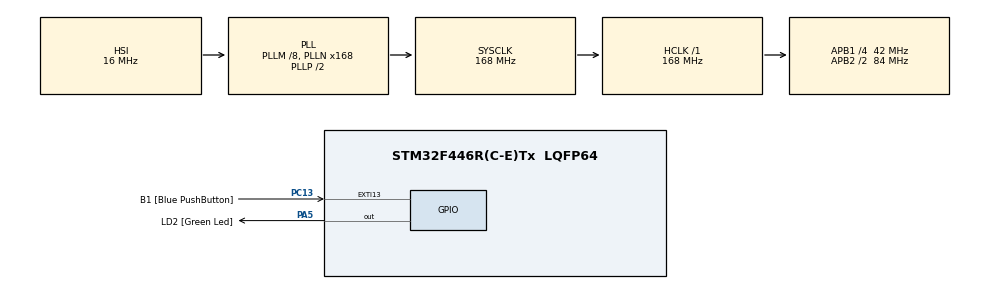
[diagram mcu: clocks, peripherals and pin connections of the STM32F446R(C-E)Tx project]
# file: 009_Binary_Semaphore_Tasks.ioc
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Mcu.Family=STM32F4
Mcu.Name=STM32F446R(C-E)Tx
Mcu.Package=LQFP64
NVIC.PriorityGroup=NVIC_PRIORITYGROUP_4
NVIC.TIM5_IRQn=true\:0\:0\:false\:false\:true\:false\:true\:true
NVIC.TimeBase=TIM5_IRQn
NVIC.TimeBaseIP=TIM5
PA13.GPIO_Label=TMS
PA13.Signal=SYS_JTMS-SWDIO
PA14.GPIO_Label=TCK
PA14.Signal=SYS_JTCK-SWCLK
PA2.GPIO_Label=USART_TX
PA2.Signal=USART2_TX
PA3.GPIO_Label=USART_RX
PA3.Signal=USART2_RX
PA5.GPIO_Label=LD2 [Green Led]
PA5.Signal=GPIO_Output
PB3.GPIO_Label=SWO
PB3.Signal=SYS_JTDO-SWO
PC13.GPIO_Label=B1 [Blue PushButton]
PC13.GPIO_ModeDefaultEXTI=GPIO_MODE_IT_FALLING
PC13.Signal=GPXTI13
PC14-OSC32_IN.Signal=RCC_OSC32_IN
PC15-OSC32_OUT.Signal=RCC_OSC32_OUT
PH0-OSC_IN.Signal=RCC_OSC_IN
PH1-OSC_OUT.Signal=RCC_OSC_OUT
ProjectManager.HeapSize=0x200
ProjectManager.StackSize=0x400
ProjectManager.TargetToolchain=STM32CubeIDE
RCC.AHBFreq_Value=168000000
RCC.APB1CLKDivider=RCC_HCLK_DIV4
RCC.APB1Freq_Value=42000000
RCC.APB1TimFreq_Value=84000000
RCC.APB2CLKDivider=RCC_HCLK_DIV2
RCC.APB2Freq_Value=84000000
RCC.APB2TimFreq_Value=168000000
RCC.CortexFreq_Value=168000000
RCC.FLatency-AdvancedSettings=FLASH_LATENCY_5
RCC.HCLKFreq_Value=168000000
RCC.HSE_VALUE=8000000
RCC.HSI_VALUE=16000000
RCC.LSE_VALUE=32768
RCC.PLLM=8
RCC.PLLN=168
RCC.SYSCLKFreq_VALUE=168000000
RCC.SYSCLKSource=RCC_SYSCLKSOURCE_PLLCLK
RCC.USBFreq_Value=168000000
RCC.VCOOutputFreq_Value=336000000
VP_SYS_VS_tim5.Mode=TIM5
board=NUCLEO-F446RE

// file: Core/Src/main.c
/* USER CODE BEGIN Header */
/**
  ******************************************************************************
  * @file           : main.c
  * @brief          : Main program body
  ******************************************************************************
  * @attention
  *
  * Copyright (c) 2023 STMicroelectronics.
  * All rights reserved.
  *
  * This software is licensed under terms that can be found in the LICENSE file
  * in the root directory of this software component.
  * If no LICENSE file comes with this software, it is provided AS-IS.
  *
  ******************************************************************************
  */
/* USER CODE END Header */
#include "main.h"

/* USER CODE BEGIN PD */

//#define DWT_CTRL    (*(volatile uint32_t*)0xE0001000)

/* USER CODE END PD */

void SystemClock_Config(void);
static void MX_GPIO_Init(void);
/* USER CODE BEGIN PFP */

//function prototypes
//static void prvSetupHardware(void);
//void printmsg(char *msg);
//static void prvSetupUart(void);
//void prvSetupGpio(void);

// Task Creation
TaskHandle_t xTaskHandleM=NULL;
TaskHandle_t xTaskHandleE=NULL;
void vManagerTask(void* pvParameters);
void vEmployeeTask(void* pvParameters);

// Binary Semaphore used to Synchronization of Manager and Employee
xSemaphoreHandle xWork;

// Queue for the Manager to put the work ticket id
xQueueHandle xWorkQueue;

char* usr_msg[250] = {0};

/* USER CODE END PFP */

int main(void)
{

  /* MCU Configuration--------------------------------------------------------*/

  /* Reset of all peripherals, Initializes the Flash interface and the Systick. */
  HAL_Init();

  /* Configure the system clock */
  SystemClock_Config();

  /* Initialize all configured peripherals */
  MX_GPIO_Init();
  /* USER CODE BEGIN 2 */

  // Segger event time stamp
  DWT->CTRL |= (1 << 0);

  // Reset the RCC clock configuration to default reset state
  RCC_DeInit();

  // Update the SystemCoreClock variable
  SystemCoreClockUpdate();

//  prvSetupHardware();

  // Start Recording
//  SEGGER_SYSVIEW_Conf();
//  SEGGER_SYSVIEW_Start();

  sprintf(usr_msg, "Demo of Binary Semaphore usage between 2 Tasks \r\n");
  printf(usr_msg);

  // Explicitly Created Semaphore
  vSemaphoreCreateBinary(xWork);

  // Queue is created to hold a maximum of 1 Element
  xWorkQueue = xQueueCreate( 1, sizeof(unsigned int));

  // Check the Semaphore and Queue was created successfully
  if( (xWork != NULL) && (xWorkQueue != NULL)){

	  // Create the Manager Task
	  xTaskCreate( vManagerTask, "Manager", 500, NULL, 3, NULL);

	  // Create a Employee Task
	  xTaskCreate( vEmployeeTask, "Employee", 500, NULL, 1, NULL);

	  // Start the Scheduler
	  vTaskStartScheduler();
  }

  sprintf(usr_msg, "Queue/Sema create failed.. \r\n");
  printf(usr_msg);

  /* USER CODE END 2 */

  /* Infinite loop */
  while (1)
  {

  }
}

void SystemClock_Config(void)
{
  RCC_OscInitTypeDef RCC_OscInitStruct = {0};
  RCC_ClkInitTypeDef RCC_ClkInitStruct = {0};

  /** Configure the main internal regulator output voltage
  */
  __HAL_RCC_PWR_CLK_ENABLE();
  __HAL_PWR_VOLTAGESCALING_CONFIG(PWR_REGULATOR_VOLTAGE_SCALE1);

  /** Initializes the RCC Oscillators according to the specified parameters
  * in the RCC_OscInitTypeDef structure.
  */
  RCC_OscInitStruct.OscillatorType = RCC_OSCILLATORTYPE_HSI;
  RCC_OscInitStruct.HSIState = RCC_HSI_ON;
  RCC_OscInitStruct.HSICalibrationValue = RCC_HSICALIBRATION_DEFAULT;
  RCC_OscInitStruct.PLL.PLLState = RCC_PLL_ON;
  RCC_OscInitStruct.PLL.PLLSource = RCC_PLLSOURCE_HSI;
  RCC_OscInitStruct.PLL.PLLM = 8;
  RCC_OscInitStruct.PLL.PLLN = 168;
  RCC_OscInitStruct.PLL.PLLP = RCC_PLLP_DIV2;
  RCC_OscInitStruct.PLL.PLLQ = 2;
  RCC_OscInitStruct.PLL.PLLR = 2;
  if (HAL_RCC_OscConfig(&RCC_OscInitStruct) != HAL_OK)
  {
    Error_Handler();
  }

  /** Initializes the CPU, AHB and APB buses clocks
  */
  RCC_ClkInitStruct.ClockType = RCC_CLOCKTYPE_HCLK|RCC_CLOCKTYPE_SYSCLK
                              |RCC_CLOCKTYPE_PCLK1|RCC_CLOCKTYPE_PCLK2;
  RCC_ClkInitStruct.SYSCLKSource = RCC_SYSCLKSOURCE_PLLCLK;
  RCC_ClkInitStruct.AHBCLKDivider = RCC_SYSCLK_DIV1;
  RCC_ClkInitStruct.APB1CLKDivider = RCC_HCLK_DIV4;
  RCC_ClkInitStruct.APB2CLKDivider = RCC_HCLK_DIV2;

  if (HAL_RCC_ClockConfig(&RCC_ClkInitStruct, FLASH_LATENCY_5) != HAL_OK)
  {
    Error_Handler();
  }
}

static void MX_GPIO_Init(void)
{
  GPIO_InitTypeDef GPIO_InitStruct = {0};

  /* GPIO Ports Clock Enable */
  __HAL_RCC_GPIOC_CLK_ENABLE();
  __HAL_RCC_GPIOH_CLK_ENABLE();
  __HAL_RCC_GPIOA_CLK_ENABLE();
  __HAL_RCC_GPIOB_CLK_ENABLE();

  /*Configure GPIO pin Output Level */
  HAL_GPIO_WritePin(LD2_GPIO_Port, LD2_Pin, GPIO_PIN_RESET);

  /*Configure GPIO pin : B1_Pin */
  GPIO_InitStruct.Pin = B1_Pin;
  GPIO_InitStruct.Mode = GPIO_MODE_IT_FALLING;
  GPIO_InitStruct.Pull = GPIO_NOPULL;
  HAL_GPIO_Init(B1_GPIO_Port, &GPIO_InitStruct);

  /*Configure GPIO pins : USART_TX_Pin USART_RX_Pin */
  GPIO_InitStruct.Pin = USART_TX_Pin|USART_RX_Pin;
  GPIO_InitStruct.Mode = GPIO_MODE_AF_PP;
  GPIO_InitStruct.Pull = GPIO_NOPULL;
  GPIO_InitStruct.Speed = GPIO_SPEED_FREQ_VERY_HIGH;
  GPIO_InitStruct.Alternate = GPIO_AF7_USART2;
  HAL_GPIO_Init(GPIOA, &GPIO_InitStruct);

  /*Configure GPIO pin : LD2_Pin */
  GPIO_InitStruct.Pin = LD2_Pin;
  GPIO_InitStruct.Mode = GPIO_MODE_OUTPUT_PP;
  GPIO_InitStruct.Pull = GPIO_NOPULL;
  GPIO_InitStruct.Speed = GPIO_SPEED_FREQ_LOW;
  HAL_GPIO_Init(LD2_GPIO_Port, &GPIO_InitStruct);

}

/* USER CODE BEGIN 4 */

void vManagerTask( void* pvParameters){

	unsigned int xWorkTicketId;
	portBASE_TYPE xStatus;

	// Semaphore is created as empty state so it needs to be "given" first
	xSemaphoreGive(xWork);

	while(1){

		// get a work ticket id
		xWorkTicketId = ( rand() & 0x1FF );

		// Send work ticket id to the work queue
		xStatus = xQueueSend( xWorkQueue, &xWorkTicketId, portMAX_DELAY);

		if( xStatus != pdPASS){
			sprintf(usr_msg, "Could not send to the queue.\r\n");
			printf(usr_msg);
		}else{
			// Manager Notifying the Employee by "Giving Semaphore
			xSemaphoreGive(xWork);
			// After assigning the work yeild the processor
			taskYIELD();
		}
	}
}

void EmployeeDoWork(unsigned char TicketId){

	// Implement the work according to the TicketId
	sprintf(usr_msg, "Employee Task: Working on Ticket Id: %d\r\n", TicketId);
	printf(usr_msg);
	vTaskDelay(TicketId);
}

void vEmployeeTask(void* pvParameters){

	unsigned char xWorkTicketId;
	portBASE_TYPE xStatus;

	while(1){

		// Employee Tries to take the Semaphore if available
		xSemaphoreTake(xWork, 0);

		// Try to get the TicketId from the Work Queue
		xStatus = xQueueReceive( xWorkQueue, &xWorkTicketId, 0);

		if( xStatus == pdPASS){
			EmployeeDoWork(xWorkTicketId);
		}else{
			// Didn't receive anything from the queue
			sprintf(usr_msg, "Employee Task: Queue is empty, nothing to do.\r\n");
			printf(usr_msg);
		}

	}
}

//static void prvSetupHardware(void)
//{
//	//Setup Button and LED
//	prvSetupGpio();
//
//	//setup UART2
//	prvSetupUart();
//}

//void printmsg(char *msg)
//{
//	for(uint32_t i=0; i < strlen(msg); i++)
//	{
//		while ( USART_GetFlagStatus(USART2,USART_FLAG_TXE) != SET);
//		USART_SendData(USART2,msg[i]);
//	}
//
//	while ( USART_GetFlagStatus(USART2,USART_FLAG_TC) != SET);
//
//}

//
//static void prvSetupUart(void)
//{
//	GPIO_InitTypeDef gpio_uart_pins;
//	USART_InitTypeDef uart2_init;
//
//	//1. Enable the UART2  and GPIOA Peripheral clock
//	RCC_APB1PeriphClockCmd(RCC_APB1Periph_USART2,ENABLE);
//	RCC_AHB1PeriphClockCmd(RCC_AHB1Periph_GPIOA,ENABLE);
//
//	//PA2 is UART2_TX, PA3 is UART2_RX
//
//	//2. Alternate function configuration of MCU pins to behave as UART2 TX and RX
//
//	//zeroing each and every member element of the structure
//	memset(&gpio_uart_pins,0,sizeof(gpio_uart_pins));
//
//	gpio_uart_pins.GPIO_Pin = GPIO_Pin_2 | GPIO_Pin_3;
//	gpio_uart_pins.GPIO_Mode = GPIO_Mode_AF;
//	gpio_uart_pins.GPIO_PuPd = GPIO_PuPd_UP;
//	gpio_uart_pins.GPIO_OType= GPIO_OType_PP;
//	gpio_uart_pins.GPIO_Speed = GPIO_High_Speed;
//	GPIO_Init(GPIOA, &gpio_uart_pins);
//
//
//	//3. AF mode settings for the pins
//	GPIO_PinAFConfig(GPIOA,GPIO_PinSource2,GPIO_AF_USART2); //PA2
//	GPIO_PinAFConfig(GPIOA,GPIO_PinSource3,GPIO_AF_USART2); //PA3
//
//	//4. UART parameter initializations
//	//zeroing each and every member element of the structure
//	memset(&uart2_init,0,sizeof(uart2_init));
//
//	uart2_init.USART_BaudRate = 115200;
//	uart2_init.USART_HardwareFlowControl = USART_HardwareFlowControl_None;
//	uart2_init.USART_Mode =  USART_Mode_Tx | USART_Mode_Rx;
//	uart2_init.USART_Parity = USART_Parity_No;
//	uart2_init.USART_StopBits = USART_StopBits_1;
//	uart2_init.USART_WordLength = USART_WordLength_8b;
//	USART_Init(USART2,&uart2_init);
//
//
//	//5. Enable the UART2 peripheral
//	USART_Cmd(USART2,ENABLE);
//
//}

//void prvSetupGpio(void)
//{
//	// this function is board specific
//
//	//Peripheral clock enable for GPIOA and GPIOC
//	RCC_AHB1PeriphClockCmd(RCC_AHB1Periph_GPIOA,ENABLE);
//	RCC_AHB1PeriphClockCmd(RCC_AHB1Periph_GPIOC,ENABLE);
//	RCC_APB2PeriphClockCmd(RCC_APB2Periph_SYSCFG,ENABLE);
//
//	GPIO_InitTypeDef led_init, button_init;
//	led_init.GPIO_Mode = GPIO_Mode_OUT;
//	led_init.GPIO_OType = GPIO_OType_PP;
//	led_init.GPIO_Pin = GPIO_Pin_5;
//	led_init.GPIO_Speed = GPIO_Low_Speed;
//	led_init.GPIO_PuPd = GPIO_PuPd_NOPULL;
//	GPIO_Init(GPIOA,&led_init);
//
//	button_init.GPIO_Mode = GPIO_Mode_IN;
//	button_init.GPIO_OType = GPIO_OType_PP;
//	button_init.GPIO_Pin = GPIO_Pin_13;
//	button_init.GPIO_Speed = GPIO_Low_Speed;
//	button_init.GPIO_PuPd = GPIO_PuPd_NOPULL;
//	GPIO_Init(GPIOC,&button_init);
//
//}
/* USER CODE END 4 */

void HAL_TIM_PeriodElapsedCallback(TIM_HandleTypeDef *htim)
{
  if (htim->Instance == TIM5) {
    HAL_IncTick();
  }
}

void Error_Handler(void)
{
  __disable_irq();
  while (1)
  {
  }
}
